# rCSL_spi_001 register map
Vendor: Texas Instruments
Peripheral module from a debugger description file (folder OMAPL138_C6748).
Registers are 32-bit, access not given, reset 0x0 unless marked. A register's access mark holds for its fields unless they carry their own. Offsets are as the file gives them; lines under a group give offsets from that group; [hi:lo] are bit positions; {n}, {i} and the like mark numbered series; 'fields as' and 'values as' point back to an identical list; <NAME> marks a mode.

## SPI — Serial Peripheral Interface
0x00 SPIGCR0 — Global Control Register 0
  [0] RESET rw
    0=IN_RESET; 1=OUT_OF_RESET
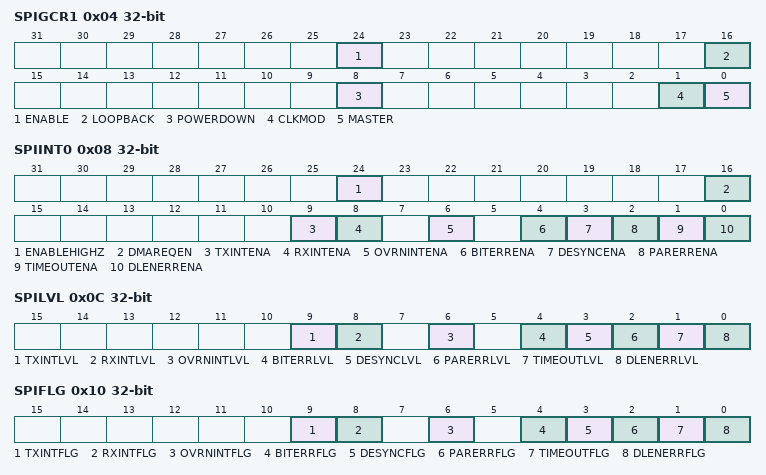
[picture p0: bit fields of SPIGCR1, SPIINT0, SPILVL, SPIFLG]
0x04 SPIGCR1 — Global Control Register 1
  [24] ENABLE rw — SPI enable
    0=DISABLE; 1=ENABLE
  [16] LOOPBACK rw — Internal loop-back test mode
    0=DISABLE; 1=ENABLE
  [8] POWERDOWN rw — Powerdown mode
    0=DISABLE; 1=ENABLE
  [1] CLKMOD rw — Clock mode
    0=EXTERNAL; 1=INTERNAL
  [0] MASTER rw — Master/Slave mode
    0=SLAVE; 1=MASTER
0x08 SPIINT0 — Interrupt Register
  [all] fields
    0=DISABLE; 1=ENABLE
  [24] ENABLEHIGHZ rw — SPIENA pin high-z enable
  [16] DMAREQEN rw — DMA request enable
  [9] TXINTENA rw — Transmit interrupt enable
  [8] RXINTENA rw — Receive interrupt enable
  [6] OVRNINTENA rw — Receive overrun interrupt enable
  [4] BITERRENA rw — Bit error interrupt enable
  [3] DESYNCENA rw — De-synchronized slave interrupt enable
  [2] PARERRENA rw — Parity error interrupt enable
  [1] TIMEOUTENA rw — ENA signal time-out interrupt enable
  [0] DLENERRENA rw — Data length error innterrupt enable
0x0C SPILVL — Level Register
  [all] fields
    0=INT0; 1=INT1
  [9] TXINTLVL rw — Transmit interrupt level
  [8] RXINTLVL rw — Receive interrupt level
  [6] OVRNINTLVL rw — Receive Overrun interrupt level
  [4] BITERRLVL rw — Bit error interrupt level
  [3] DESYNCLVL rw — De-synchronized slave interrupt level
  [2] PARERRLVL rw — Parity error interrupt level
  [1] TIMEOUTLVL rw — ENA signal time-out interrupt level
  [0] DLENERRLVL rw — Data length error interrupt level
0x10 SPIFLG — Flag Register
  [9] TXINTFLG ro — Transmit empty flag
    0=NO_EMPTY; 1=EMPTY
  [8] RXINTFLG — Receive full flag (access RC)
    0=NO_FULL; 1=FULL
  [6] OVRNINTFLG — Receive overrun flag (access RC)
    0=NO_ERROR; 1=ERROR
  [4] BITERRFLG — Bit error flag (access RC)
    0=NO_ERROR; 1=ERROR
  [3] DESYNCFLG — De-synchronized slave flag (access RC)
    0=NO_ERROR; 1=ERROR
  [2] PARERRFLG — Parity error flag (access RC)
    0=NO_ERROR; 1=ERROR
  [1] TIMEOUTFLG — ENA signal time-out flag (access RC)
    0=NO_ERROR; 1=ERROR
  [0] DLENERRFLG — Data Length error flag (access RC)
    0=NO_ERROR; 1=ERROR
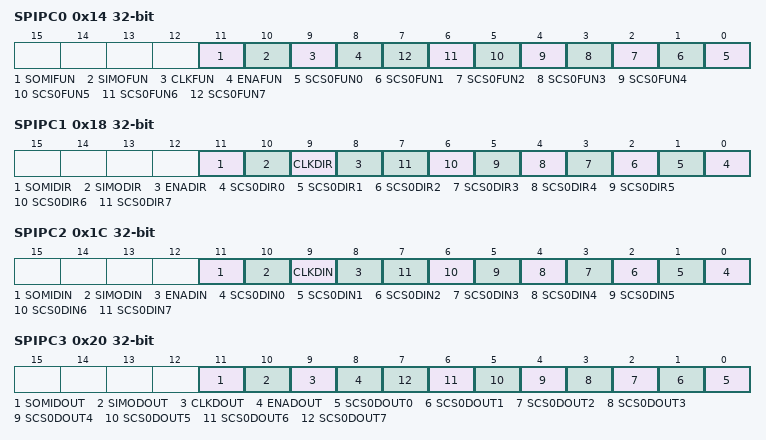
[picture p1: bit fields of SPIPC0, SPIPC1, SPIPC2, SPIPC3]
0x14 SPIPC0 — Pin Control Register 0
  [all] fields
    0=GPIO; 1=SPI
  [11] SOMIFUN rw — SOMI function
  [10] SIMOFUN rw — SIMO function
  [9] CLKFUN rw — CLK function
  [8] ENAFUN rw — ENA function
  [n] SCS0FUN{n} rw (n=0..7) — SCS{n} function
0x18 SPIPC1 — Pin Control Register 1
  [all] fields
    0=INPUT; 1=OUTPUT
  [11] SOMIDIR rw — SOMI direction
  [10] SIMODIR rw — SIMO direction
  [9] CLKDIR rw — CLK direction
  [8] ENADIR rw — ENA direction
  [n] SCS0DIR{n} rw (n=0..7) — SCS{n} direction
0x1C SPIPC2 — Pin Control Register 2
  [all] fields
    0=LOW; 1=HIGH
  [11] SOMIDIN ro — SOMI data in
  [10] SIMODIN ro — SIMO data in
  [9] CLKDIN ro — Clock data in
  [8] ENADIN ro — ENA data in
  [n] SCS0DIN{n} ro (n=0..7) — SCS{n} data in
0x20 SPIPC3 — Pin Control Register 3
  [all] fields
    0=LOW; 1=HIGH
  [11] SOMIDOUT rw — SOMI dataout write
  [10] SIMODOUT rw — SIMO dataout write
  [9] CLKDOUT rw — CLK dataout write
  [8] ENADOUT rw — ENA dataout write
  [n] SCS0DOUT{n} rw (n=0..7) — SCS{n} dataout write
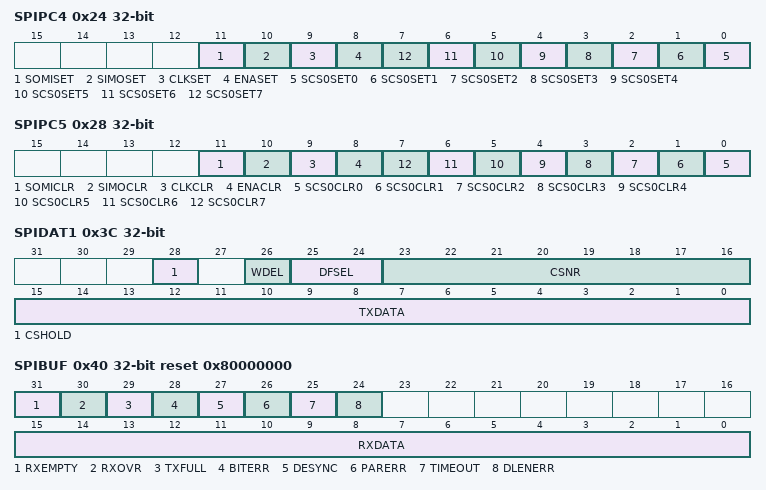
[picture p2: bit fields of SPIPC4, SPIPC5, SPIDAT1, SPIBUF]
0x24 SPIPC4 — Pin Control Register 4
  [all] fields
    0=NO_EFFECT; 1=SET
  [11] SOMISET rw — SOMI dataout set
  [10] SIMOSET rw — SIMO dataout set
  [9] CLKSET rw — CLK dataout set
  [8] ENASET rw — ENA dataout set
  [n] SCS0SET{n} rw (n=0..7) — SCS{n} dataout set
0x28 SPIPC5 — Pin Control Register 5
  [all] fields
    0=NO_EFFECT; 1=CLEAR
  [11] SOMICLR rw — SOMI dataout clear
  [10] SIMOCLR rw — SIMO dataout clear
  [9] CLKCLR rw — CLK dataout clear
  [8] ENACLR rw — ENA dataout clear
  [n] SCS0CLR{n} rw (n=0..7) — SCS{n} dataout clear
0x38 SPIDAT0 — Transmit Data Register 0
  [15:0] TXDATA rw — Transmit Data
0x3C SPIDAT1 — Transmit Data Register 1
  [28] CSHOLD rw — Chip select hold mode
    0=DISABLE; 1=ENABLE
  [26] WDEL rw — Delay in between transmissions
    0=DISABLE; 1=ENABLE
  [25:24] DFSEL rw — Data format select
    {v}=FORMAT{v} (v=0..3)
  [23:16] CSNR rw — Chip select number
  [15:0] TXDATA rw — Transmit Data
0x40 SPIBUF reset 0x80000000 — Receive Buffer Register
  [31] RXEMPTY — Receive empty (access RS)
    0=NO_EMPTY; 1=EMPTY
  [30] RXOVR — Receive overrun (access RC)
    0=NO_ERROR; 1=ERROR
  [29] TXFULL ro — Transmit full
    0=NO_FULL; 1=FULL
  [28] BITERR — Bit error (access RC)
    0=NO_ERROR; 1=ERROR
  [27] DESYNC — De-synchronized slave (access RC)
    0=NO_ERROR; 1=ERROR
  [26] PARERR — Parity error (access RC)
    0=NO_ERROR; 1=ERROR
  [25] TIMEOUT — ENA signal time-out (access RC)
    0=NO_ERROR; 1=ERROR
  [24] DLENERR — Data length error (access RC)
    0=NO_ERROR; 1=ERROR
  [15:0] RXDATA ro — Receive data
0x44 SPIEMU — Emulation Register
  [15:0] RXDATA ro — Receive data
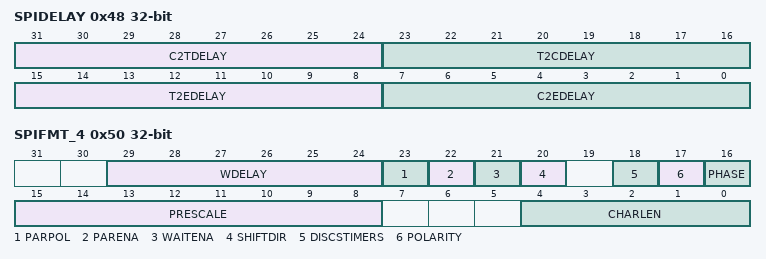
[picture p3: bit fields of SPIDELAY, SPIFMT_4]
0x48 SPIDELAY rw — Delay Register
  [31:24] C2TDELAY — Chip select active to transmit start delay
  [23:16] T2CDELAY — Transmit end to chip select inactive delay
  [15:8] T2EDELAY — Transmit data finished to ENA pin inactive timeout
  [7:0] C2EDELAY — Chip select active to ENA signal active timeout
0x4C SPIDEF reset 0x1 — Default Chip select Regsiter
  [0] CSDEF0 rw — Chip select default pattern
    0=LOW; 1=HIGH
0x50 SPIFMT_4 — Format 0 Register
  [29:24] WDELAY rw — Delay in between transmissions
  [23] PARPOL rw — Parity polarity
    0=EVEN; 1=ODD
  [22] PARENA rw — Parity enable
    0=DISABLE; 1=ENABLE
  [21] WAITENA rw — Master waits for ENA signal from slave
    0=DISABLE; 1=ENABLE
  [20] SHIFTDIR rw — Shift direction
    0=MSB; 1=LSB
  [18] DISCSTIMERS rw — Disable chip select timers
    0=DISABLE; 1=ENABLE
  [17] POLARITY rw — Clock polarity
    0=LOW; 1=HIGH
  [16] PHASE rw — Clock delay
    0=NO_DELAY; 1=DELAY
  [15:8] PRESCALE rw — Prescaler
  [4:0] CHARLEN rw — Data word length
0x60 INTVEC_2 — Interrupt Vector Register
  [5:1] INTVECT ro — Interrupt vector
